# MLB register map
Vendor: Texas Instruments
Peripheral module from a debugger description file (folder 66AK2G0x_66AK2G1x).
Registers are 32-bit, read-write, reset 0x0 unless marked. A register's access mark holds for its fields unless they carry their own. Offsets are as the file gives them; lines under a group give offsets from that group; [hi:lo] are bit positions; {n}, {i} and the like mark numbered series; 'fields as' and 'values as' point back to an identical list; <NAME> marks a mode.

## MLB
0x00 MLB_MLBSSREV ro reset 0x4A080100
  [31:0] REV — TI internal data. Identifies revision of peripheral.
0x04 MLB_MLBSSPWR access per field
  [0] MSTANDBY rw — Value to be driven in the MStandby bus of the power management interface Writing a 1 to this bit asserts the MStandby output of MLBSS, thereby initiating the clock disabling sequence for the MLBSS. Write 0 to this register to enable the clock for MLBSS. 0h: Mstandby output is deasserted 1h: Mstandby output is asserted
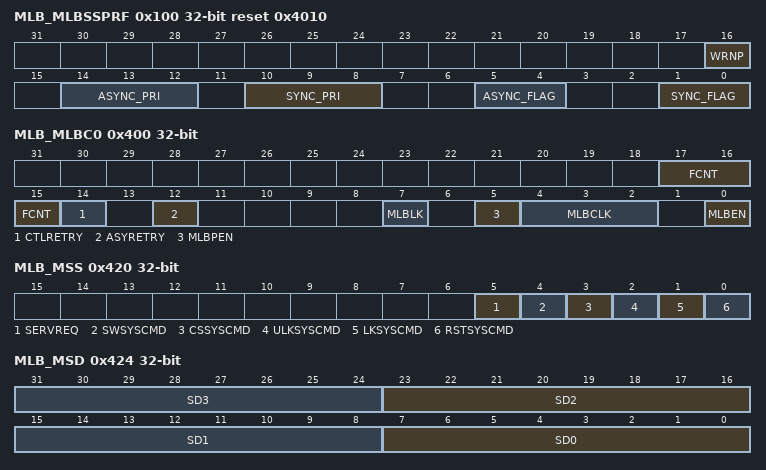
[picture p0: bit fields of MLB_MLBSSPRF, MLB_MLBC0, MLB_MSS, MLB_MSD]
0x100 MLB_MLBSSPRF access per field reset 0x4010
  [16] WRNP rw — The WRNP bit controls whether the writes issued by the DMA interface are posted (no write response required to complete transaction) or non posted (write response required to complete transaction). 0h: Only posted writes are issued. This means that the performance of DMA writes would be better, but the writes will complete before the data gets written to the destination. Posted writes do not require a write response from the destination to complete a write transaction. 1h: Only non-posted writes are issued. This means that the performance of DMA writes would be lesser, but would guarantee that when a write has completed, the data gets written into the final destination. Non posted writes require a write response from the destination to complete a write transaction. It is recommended to use only posted writes for better performance. This is a static configuration out of reset based on performance requirements and changing it while a transfer in progress could cause indeterminate behavior.
  [14:12] ASYNC_PRI rw — ASYNC_PRI controls the priority carried in MREQINFO attribute of DMA interface, when a asynchronous transaction is requested at the DMA interface. It is recommended that the ASYNC_PRI be set at lower priority compared to other masters in the system, as these transactions are not time-critical. 0h: Highest priority 7h: Lowest priority
  [10:8] SYNC_PRI rw — SYNC_PRI controls the priority carried in MREQINFO attribute of DMA interface, when a synchronous transaction is requested at the DMA interface. It is recommended that the SYNC_PRI be set at a reasonably higher priority compared to other masters in the system, as these transactions could be time-critical. 0h: Highest priority 7h: Lowest priority
  [5:4] ASYNC_FLAG rw — ASYNC_FLAG controls the value carried in MFLAG attribute of DMA interface. This attribute is used in determining the priority of these transactions through the TeraNet_DMA infrastructure. It is recommended that he ASYNC_FLAG be set at lower priority compared to other masters in the system, as these transactions are not time-critical 0h: Lowest priority through on-chip network 1h: Medium priority through on-chip network 2h: Reserved 3h: Highest priority through on-chip network
  [1:0] SYNC_FLAG rw — SYNC_FLAG controls the value carried in MFLAG attribute of DMA interface. This attribute is used in determining the priority of these transactions through the TeraNet_DMA infrastructure. It is recommended that the SYNC_FLAG be set at reasonably higher priority compared to other masters in the system, as these transactions are time-critical. 0h: Lowest priority through on-chip network 1h: Medium priority through on-chip network 2h: Reserved 3h: Highest priority through on-chip network
0x400 MLB_MLBC0 access per field
  [17:15] FCNT rw — The number of frames per sub-buffer for synchronous channels 0h: 1 frame per sub-buffer (operation is the same as standard mode) 1h: 2 frames per sub-buffer 2h: 4 frames per sub-buffer 3h: 8 frames per sub-buffer 4h: 16 frames per sub-buffer 5h: 32 frames per sub-buffer 6h: 64 frames per sub-buffer 7h: Reserved
  [14] CTLRETRY rw — Control Tx packet retry. When cleared, a control packet that is flagged with a Break or ProtocolError by the receiver is skipped. When set, a control packet that is flagged with a Break or ProtocolError by the receiver is re-transmitted. 0h: Control packet is skipped 1h: Control packet is re-transmitted
  [12] ASYRETRY rw — Asynchronous Tx packet retry. When cleared, an asynchronous packet that is flagged with a Break or ProtocolError by the receiver is skipped. When set, an asynchronous packet that is flagged with a Break or ProtocolError by the receiver is re-transmitted. 0h: Asynchronous packet is skipped 1h: Asynchronous packet is re-transmitted
  [7] MLBLK ro — MediaLB lock status. When set, indicates that the MediaLB block is synchronized to the incoming MediaLB frame. If MLBLK is clear (unlocked), MLBLK is set after FRAMESYNC is detected at the same position for three consecutive frames. If MLBLK is set (locked), MLBLK is cleared after not receiving FRAMESYNC at the expected time for two consecutive frames. While MLBLK is set, FRAMESYNC patterns occurring at locations other than the expected one are ignored. Read-only. 0h: MediaLB is unlocked 1h: MediaLB is locked
  [5] MLBPEN rw — MediaLB 6-pin enable. 0h: MediaLB 3-pin interface enabled 1h: MediaLB 6-pin interface enabled
  [4:2] MLBCLK rw — MediaLB clock speed select. 0h: 256 -Fs (for MLBPEN = 0) 1h: 512 -Fs (for MLBPEN = 0) 2h: 1024 -Fs (for MLBPEN = 0) 3h: 2048xFs (for MLBPEN = 1) 4h-7h: Reserved
  [0] MLBEN rw — MediaLB enable. When set, MediaLB clock, signal, and data are received and transmitted on the appropriate MediaLB pins. 0h: MediaLB disabled 1h: MediaLB enabled
0x40C MLB_MS0 access not given
  [31:0] MCS — MediaLB channel status. Indicates the channel status for MediaLB channels 31 to 0. Channel status bits are set by hardware and cleared by software. Status is only set if the appropriate bits in the MIEN register are set. 0h: A channel status bit is cleared (applies for all bits in this register) 1h: A channel status bit is set (applies for all bits in this register) (access RW0C)
0x414 MLB_MS1 access not given
  [31:0] MCS — MediaLB channel status. Indicates the channel status for MediaLB channels 63 to 32. Channel status bits are set by hardware and cleared by software. Status is only set if the appropriate bits in the MIEN register are set. 0h: A channel status bit is cleared (applies for all bits in this register) 1h: A channel status bit is set (applies for all bits in this register) (access RW0C)
0x420 MLB_MSS access not given
  [5] SERVREQ rw — Service request enabled. When cleared, the MediaLB block responds with a 'device present' system response. When set, the MediaLB block responds with a 'device present, request service' system response if a matching channel scan system command is detected. 0h: Service request disabled (not detected) 1h: Service request enabled (detected)
  [4] SWSYSCMD — Software system command detected (in the system quadlet). Set by hardware, cleared by software. Data is stored in the 0h: Software system command not detected 1h: Software system command detected (access RW0C)
  [3] CSSYSCMD — Channel scan system command detected (in the system quadlet). Set by hardware, cleared by software. If the node address specified in Data quadlet matches the value in MLBC1.NDA, the device responds either 'device present' or 'device present, request service' system response in the next system quadlet. 0h: Channel scan system command not detected 1h: Channel scan system command detected (access RW0C)
  [2] ULKSYSCMD — Network unlock system command detected (in the system quadlet). Set by hardware, cleared by software. 0h: Unlock system command not detected 1h: Unlock system command detected (access RW0C)
  [1] LKSYSCMD — Network lock system command detected (in the system quadlet). Set by hardware, cleared by software. 0h: Lock system not detected 1h: Lock system detected (access RW0C)
  [0] RSTSYSCMD — Reset system command detected (in the system quadlet). Set by hardware, cleared by software. 0h: Reset system command not detected 1h: Reset system command detected (access RW0C)
0x424 MLB_MSD ro
  [8n+7:8n] SD{n} (n=0..3) — System data (byte {n}). Updated with MediaLB Data[{8n+7}-{8n}] when a MediaLB software system command is received in the system quadlet. If MSS.SWSYSCMD is already set, then SD{n} is not updated. Read-only. As soon as it is serviced, the MSS.SWSYSCMD bit should be cleared.
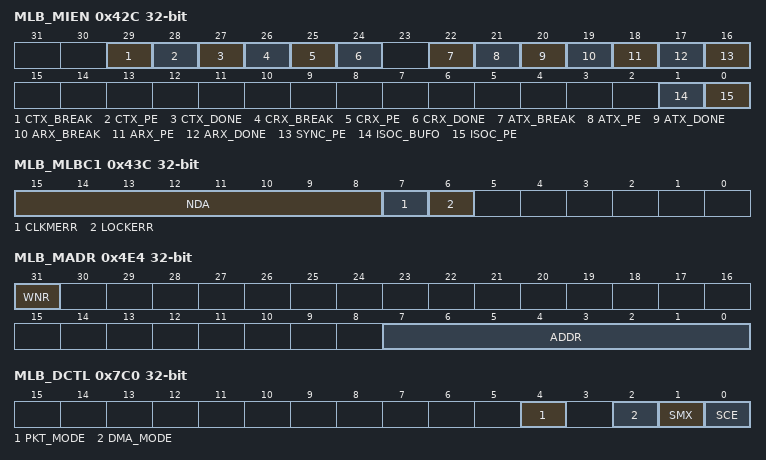
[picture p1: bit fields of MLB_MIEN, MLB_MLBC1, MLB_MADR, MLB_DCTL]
0x42C MLB_MIEN access per field
  [29] CTX_BREAK rw — Control Tx break enable. When set, a ReceiverBreak response received from the receiver on a control Tx channel causes the appropriate channel bit in the MS0 or MS1 registers to be set. 0h: Control Tx break disabled 1h: Control Tx break enabled
  [28] CTX_PE rw — Control Tx protocol error enable. When set, a ProtocolError generated by the receiver on a control Tx channel causes the appropriate channel bit in the MS0 or MS1 registers to be set. 0h: Control Tx protocol error disabled 1h: Control Tx protocol error enabled
  [27] CTX_DONE rw — Control Tx packet done enable. When set, a packet transmitted with no errors on a control Tx channel causes the appropriate channel bit in the MS0 or MS1 registers to be set. 0h: Control Tx packet done disabled 1h: Control Tx packet done enabled
  [26] CRX_BREAK rw — Control Rx break enable. When set, a ControlBreak command received from the transmitter on a control Rx channel causes the appropriate channel bit in the MS0 or MS1 registers to be set. 0h: Control Rx break disabled 1h: Control Rx break enabled
  [25] CRX_PE rw — Control Rx protocol error enable. When set, a ProtocolError detected on a control Rx channel causes the appropriate channel bit in the MS0 or MS1 registers to be set. 0h: Control Rx protocol error disabled 1h: Control Rx protocol error enabled
  [24] CRX_DONE rw — Control Rx packet done enable. When set, a packet received with no errors on a control Rx channel causes the appropriate channel bit in the MS0 or MS1 registers to be set. 0h: Control Rx packet done disabled 1h: Control Rx packet done enabled
  [22] ATX_BREAK rw — Asynchronous Tx break enable. When set, a ReceiverBreak response received from the receiver on an asynchronous Tx channel causes the appropriate channel bit in the MS0 or MS1 registers to be set. 0h: Asynchronous Tx break disabled 1h: Asynchronous Tx break enabled
  [21] ATX_PE rw — Asynchronous Tx protocol error enable. When set, a ProtocolError generated by the receiver on an asynchronous Tx channel causes the appropriate channel bit in the MS0 or MS1 registers to be set. 0h: Asynchronous Tx protocol error disabled 1h: Asynchronous Tx protocol error enabled
  [20] ATX_DONE rw — Asynchronous Tx packet done enable. When set, a packet transmitted with no errors on an asynchronous Tx channel causes the appropriate channel bit in the MS0 or MS1 registers to be set. 0h: Asynchronous Tx packet done disabled 1h: Asynchronous Tx packet done enabled
  [19] ARX_BREAK rw — Asynchronous Rx break enable. When set, a AsyncBreak command received from the transmitter on an asynchronous Rx channel causes the appropriate channel bit in the MS0 or MS1 registers to be set. 0h: Asynchronous Rx break disabled 1h: Asynchronous Rx break enabled
  [18] ARX_PE rw — Asynchronous Rx protocol error enable. When set, a ProtocolError detected on an asynchronous Rx channel causes the appropriate channel bit in the MS0 or MS1 registers to be set. 0h: Asynchronous Rx protocol error disabled 1h: Asynchronous Rx protocol error enabled
  [17] ARX_DONE rw — Asynchronous Rx packet done enable. When set, a packet received with no errors on an asynchronous Rx channel causes the appropriate channel bit in the MS0 or MS1 registers to be set. 0h: Asynchronous Rx packet done disabled 1h: Asynchronous Rx packet done enable
  [16] SYNC_PE rw — Synchronous protocol error enable. When set, a ProtocolError detected on a synchronous Rx channel causes the appropriate channel bit in the MS0 or MS1 registers to be set. 0h: Synchronous protocol error disabled 1h: Synchronous protocol error enabled
  [1] ISOC_BUFO rw — Isochronous Rx buffer overflow enable. When set, a buffer overflow on an isochronous Rx channel causes the appropriate channel bit in the MS0 or MS1 registers to be set. This occurs only when isochronous flow control is disabled. 0h: Buffer overflow disabled 1h: Buffer overflow enabled
  [0] ISOC_PE rw — Isochronous Rx protocol error enable. When set, a ProtocolError detected on an isochronous Rx channel causes the appropriate channel bit in the MS0 or MS1 registers to be set. 0h: Isochronous Rx ProtocolError disabled 1h: Isochronous Rx ProtocolError enabled
0x43C MLB_MLBC1 access not given
  [15:8] NDA rw — Node device address. Used for system commands directed to individual MediaLB nodes. All values from 00h to FFh can be used.
  [7] CLKMERR — MediaLB clock missing status. Set when MediaLB clock is not toggling at the pin, cleared by software 0h: MediaLB clock is toggling at the pins 1h: MediaLB clock is not toggling at the pins (access RW0C)
  [6] LOCKERR — MediaLB lock error status. Set when MediaLB is unlocked, cleared by software. 0h: No MediaLB lock error. Implies MediaLB is properly locked 1h: MediaLB lock error. Implies MediaLB is unlocked. Write 0 to clear (access RW0C)
0x480 MLB_DIENR access per field
  [15] EN rw — DMA enable. Always program to 1. 0h: Disabled 1h: Enabled
0x488 MLB_DICER0
  [31:0] CHE — Bitwise channel enable. Bits [31-0]. Always program to 1. 0h: Disabled (applies for all bits in this register) 1h: Enabled (applies for all bits in this register)
0x48C MLB_DICER1
  [31:0] CHE — Bitwise channel enable. Bits [63-32]. Always program to 1. 0h: Disabled (applies for all bits in this register) 1h: Enabled (applies for all bits in this register)
0x4C0 MLB_MDAT0
  [31:0] DATA — CTR data bits[31-0] of 128-bit entry or DBR data bits[7-0] of 8-bit entry
{0x4C0+4i} MLB_MDAT{i} (i=1..3)
  [31:0] DATA — CTR data bits[{32i+31}-{32i}] of 128-bit entry
{0x4D0+4i} MLB_MDWE{i} (i=0..3)
  [31:0] MASK — Bitwise write enable for CTR data bits[{32i+31}-{32i}] 0h: Disabled (applies for all bits in this register) 1h: Enabled (applies for all bits in this register)
0x4E0 MLB_MCTL access not given
  [0] XCMP — Transfer complete (write 0 to clear) 0h: Memory interface transfer not completed 1h: Memory interface transfer is completed (access RW0C)
0x4E4 MLB_MADR access per field
  [31] WNR rw — Write-Not-Read selection 0h: Read 1h: Write
  [7:0] ADDR rw — CTR address of 128-bit entry. All values from 00h to FFh can be used.
0x7C0 MLB_DCTL access per field
  [4] PKT_MODE rw — Packet mode for async/control packets. 0h: Single packet mode 1h: Multi Packet mode
  [2] DMA_MODE rw — DMA mode. 0h: DMA Mode 0 (Not supported) 1h: DMA Mode 1 (Use always this value)
  [1] SMX rw — DMA interrupt mux enable. 0h: The 1h: The
  [0] SCE rw — Software clear enable. 0h: Hardware clears interrupt after the 1h: Software clears interrupt
0x7D0 MLB_DCSR0 access not given
  [31:0] CHS — Interrupt status for logical channels 31 to 0. 0h: No interrupt (applies for all bits in this register) 1h: Interrupt (applies for all bits in this register) (access RW1C)
0x7D4 MLB_DCSR1 access not given
  [31:0] CHS — Interrupt status for logical channels 63 to 32. 0h: No interrupt (applies for all bits in this register) 1h: Interrupt (applies for all bits in this register) (access RW1C)
0x7D8 MLB_DCMR0
  [31:0] CHM — Bitwise channel mask. Bits [31-0]. 0h: Masked (applies for all bits in this register) 1h: Unmasked (applies for all bits in this register)
0x7DC MLB_DCMR1
  [31:0] CHM — Bitwise channel mask. Bits [63-32]. 0h: Masked (applies for all bits in this register) 1h: Unmasked (applies for all bits in this register)
